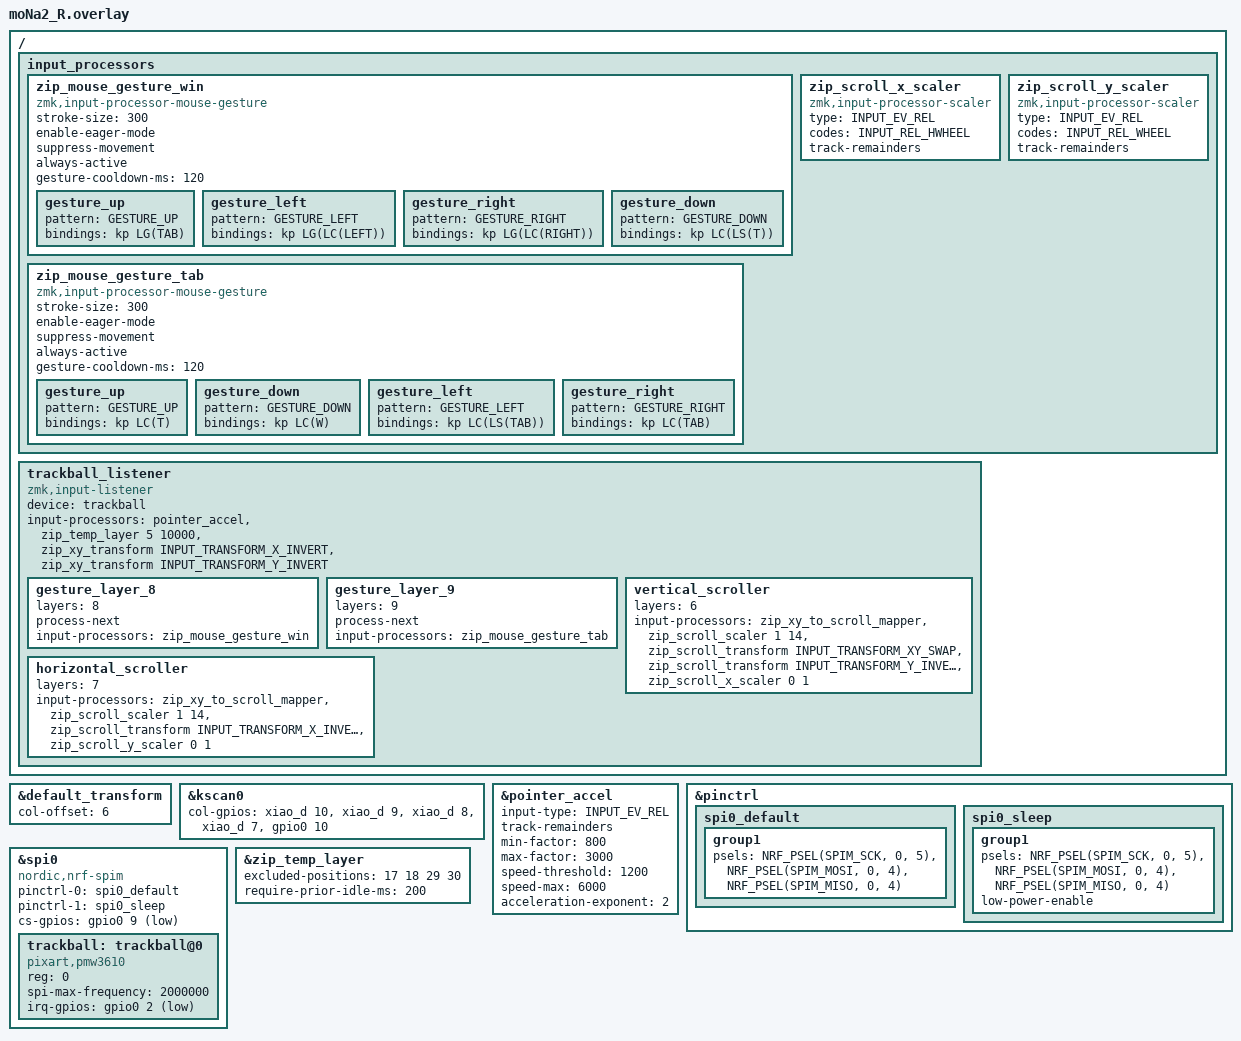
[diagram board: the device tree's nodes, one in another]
#include <behaviors/input_gestures_accel.dtsi>
#include <dt-bindings/zmk/input_transform.h>
#include <dt-bindings/zmk/keys.h>
#include <dt-bindings/zmk/mouse-gesture.h>
#include <mouse-gesture.dtsi>
#include "moNa2.dtsi"
#include <input/processors.dtsi>
#include <zephyr/dt-bindings/input/input-event-codes.h>

&default_transform {
    col-offset = <6>;
};

&kscan0 {
        col-gpios
            = <&xiao_d 10 GPIO_ACTIVE_HIGH>
            , <&xiao_d 9 GPIO_ACTIVE_HIGH> 
            , <&xiao_d 8 GPIO_ACTIVE_HIGH> 
            , <&xiao_d 7 GPIO_ACTIVE_HIGH> 
            , <&gpio0 10 GPIO_ACTIVE_HIGH>
            ;
};

// アクセラレーションの設定
&pointer_accel {
    input-type = <INPUT_EV_REL>;  // For relative input devices
    track-remainders;             // Accumulate fractional movements
    min-factor = <800>;          // 0.8x at very slow speeds
    max-factor = <3000>;         // 3.0x at fast speeds
    speed-threshold = <1200>;     // 1200 counts/sec for 1x
    speed-max = <6000>;          // 6000 counts/sec for max accel
    acceleration-exponent = <2>;  // Quadratic acceleration curve
};

/ {
    input_processors {
        // レイヤー8: Win: 上/左/右  ブラウザ: 下（タブ復元）（常時ジェスチャーモード）
        zip_mouse_gesture_win: zip_mouse_gesture_win {
            compatible = "zmk,input-processor-mouse-gesture";
            #input-processor-cells = <0>;
            stroke-size = <300>;
            enable-eager-mode;
            suppress-movement;
            always-active;
            gesture-cooldown-ms = <120>;

            // 上: アプリビュー（Win+Tab）
            gesture_up {
                pattern = <GESTURE_UP>;
                bindings = <&kp LG(TAB)>;
            };

            // 左: 仮想デスクトップを左へ（Win+Ctrl+←）
            gesture_left {
                pattern = <GESTURE_LEFT>;
                bindings = <&kp LG(LC(LEFT))>;
            };

            // 右: 仮想デスクトップを右へ（Win+Ctrl+→）
            gesture_right {
                pattern = <GESTURE_RIGHT>;
                bindings = <&kp LG(LC(RIGHT))>;
            };

            // 下: タブを復元（Ctrl+Shift+T）
            gesture_down {
                pattern = <GESTURE_DOWN>;
                bindings = <&kp LC(LS(T))>;
            };
        };

        // レイヤー9: タブ操作（常時ジェスチャーモード）
        zip_mouse_gesture_tab: zip_mouse_gesture_tab {
            compatible = "zmk,input-processor-mouse-gesture";
            #input-processor-cells = <0>;
            stroke-size = <300>;
            enable-eager-mode;
            suppress-movement;
            always-active;
            gesture-cooldown-ms = <120>;

            // 上: タブを作成（Ctrl+T）
            gesture_up {
                pattern = <GESTURE_UP>;
                bindings = <&kp LC(T)>;
            };

            // 下: タブを削除（Ctrl+W）
            gesture_down {
                pattern = <GESTURE_DOWN>;
                bindings = <&kp LC(W)>;
            };

            // 左: 前のタブへ（Ctrl+Shift+Tab）
            gesture_left {
                pattern = <GESTURE_LEFT>;
                bindings = <&kp LC(LS(TAB))>;
            };

            // 右: 次のタブへ（Ctrl+Tab）
            gesture_right {
                pattern = <GESTURE_RIGHT>;
                bindings = <&kp LC(TAB)>;
            };
        };

        zip_scroll_x_scaler: zip_scroll_x_scaler {
            compatible = "zmk,input-processor-scaler";
            #input-processor-cells = <2>;
            type = <INPUT_EV_REL>;
            codes = <INPUT_REL_HWHEEL>;
            track-remainders;
        };

        zip_scroll_y_scaler: zip_scroll_y_scaler {
            compatible = "zmk,input-processor-scaler";
            #input-processor-cells = <2>;
            type = <INPUT_EV_REL>;
            codes = <INPUT_REL_WHEEL>;
            track-remainders;
        };
    };
};

/ {
    trackball_listener {
        compatible = "zmk,input-listener";
        device = <&trackball>;
        input-processors = <
            &pointer_accel      // Acceleration processor
            &zip_temp_layer 5 10000
            // &zip_xy_scaler 2 3  // カーソル速度調整
            &zip_xy_transform INPUT_TRANSFORM_X_INVERT  // カーソル移動のX方向を反転する
            &zip_xy_transform INPUT_TRANSFORM_Y_INVERT  // カーソル移動のY方向を反転する
        >;

        gesture_layer_8 {
            layers = <8>;
            process-next;
            input-processors = <&zip_mouse_gesture_win>;
        };

        gesture_layer_9 {
            layers = <9>;
            process-next;
            input-processors = <&zip_mouse_gesture_tab>;
        };

        vertical_scroller {
            layers = <6>;
            input-processors = <
                &zip_xy_to_scroll_mapper
                &zip_scroll_scaler 1 14  // スクロール速度調整
                &zip_scroll_transform INPUT_TRANSFORM_XY_SWAP  // スクロールのXとYを入れ替える
                &zip_scroll_transform INPUT_TRANSFORM_Y_INVERT  // スクロールのY方向を反転する
                &zip_scroll_x_scaler 0 1  // スクロールを縦方向に限定する
            >;
        };

        horizontal_scroller {
            layers = <7>;
            input-processors = <
                &zip_xy_to_scroll_mapper
                &zip_scroll_scaler 1 14  // スクロール速度調整
                &zip_scroll_transform INPUT_TRANSFORM_X_INVERT  // スクロールのX方向を反転する
                &zip_scroll_y_scaler 0 1  // スクロールを横方向に限定する
            >;
        };

    };
};

&pinctrl {
    spi0_default: spi0_default {
        group1 {
            psels = <NRF_PSEL(SPIM_SCK, 0, 5)>,
                <NRF_PSEL(SPIM_MOSI, 0, 4)>,
                <NRF_PSEL(SPIM_MISO, 0, 4)>;
        };
    };

    spi0_sleep: spi0_sleep {
        group1 {
            psels = <NRF_PSEL(SPIM_SCK, 0, 5)>,
                <NRF_PSEL(SPIM_MOSI, 0, 4)>,
                <NRF_PSEL(SPIM_MISO, 0, 4)>;
            low-power-enable;
        };
    };
};

&spi0 {
    status = "okay";
    compatible = "nordic,nrf-spim";
    pinctrl-0 = <&spi0_default>;
    pinctrl-1 = <&spi0_sleep>;
    pinctrl-names = "default", "sleep";
    cs-gpios = <&gpio0 9 GPIO_ACTIVE_LOW>;

    trackball: trackball@0 {
        status = "okay";
        compatible = "pixart,pmw3610";
        reg = <0>;
        spi-max-frequency = <2000000>;
        irq-gpios = <&gpio0 2 (GPIO_ACTIVE_LOW | GPIO_PULL_UP)>;
        // automouse-layer = <5>;  // Input Processorを使用するため、zmk-pmw3610-driverのAMLは無効化
        // scroll-layers = <6>;  // Input Processorを使用するため、zmk-pmw3610-driverの設定は無効化

    };
};

// 非マウスキーを押したらタイムアウトに関係なくマウスレイヤーを抜ける
&zip_temp_layer {
    excluded-positions = <
        17  // J
        18  // k
        29  // M
        30  // ,
    >;
};

// キー入力中のオートマウスレイヤー誤爆防止
&zip_temp_layer {
    require-prior-idle-ms = <200>;
};
